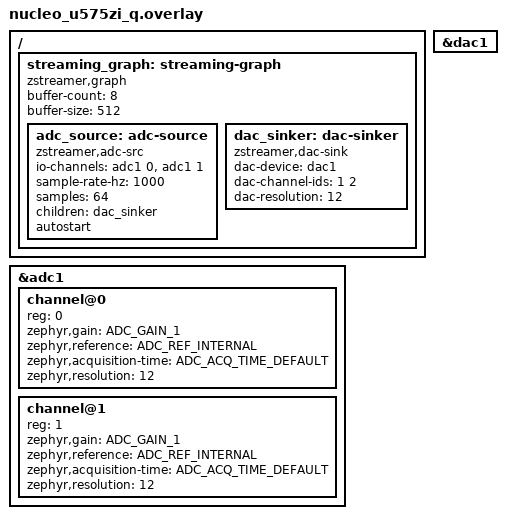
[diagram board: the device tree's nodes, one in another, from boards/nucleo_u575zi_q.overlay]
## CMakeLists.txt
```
# Copyright (c) 2026 sharonthecreator
# SPDX-License-Identifier: Apache-2.0

cmake_minimum_required(VERSION 3.20.0)
find_package(Zephyr REQUIRED HINTS $ENV{ZEPHYR_BASE})
project(adc2dac)

target_sources(app PRIVATE src/main.c)
```

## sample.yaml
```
# Copyright (c) 2026 sharonthecreator
# SPDX-License-Identifier: Apache-2.0

sample:
  name: ADC-to-DAC
  description: |
    Captures dual-channel ADC data and outputs it to a dual-channel
    DAC using a zstreamer graph with adc-src and dac-sink nodes.
    Demonstrates multi-channel ADC capture routed to multi-channel
    DAC output.
tests:
  sample.zstreamer.adc2dac:
    tags: zstreamer adc dac
    platform_allow: nucleo_u575zi_q
```

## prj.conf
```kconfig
# Copyright (c) 2026 sharonthecreator
# SPDX-License-Identifier: Apache-2.0

CONFIG_LOG=y

# zstreamer framework
CONFIG_ZSTREAMER=y

CONFIG_ZSTREAMER_ADC_SRC=y
CONFIG_ADC=y

CONFIG_ZSTREAMER_DAC_SINK=y
CONFIG_DAC=y
```

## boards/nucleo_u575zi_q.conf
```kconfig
# Copyright (c) 2026 sharonthecreator
# SPDX-License-Identifier: Apache-2.0
```

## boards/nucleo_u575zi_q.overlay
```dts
/*
 * Copyright (c) 2026 sharonthecreator
 * SPDX-License-Identifier: Apache-2.0
 *
 * ADC-to-DAC sample on Nucleo U575ZI-Q.
 *
 * Captures dual-channel 12-bit ADC data from PA0 (ADC1_IN0) and
 * PA1 (ADC1_IN1) at ~1 kHz and outputs to DAC1 channels 1 and 2.
 */

&adc1 {
	status = "okay";
	#address-cells = <1>;
	#size-cells = <0>;

	channel@0 {
		reg = <0>;
		zephyr,gain = "ADC_GAIN_1";
		zephyr,reference = "ADC_REF_INTERNAL";
		zephyr,acquisition-time = <ADC_ACQ_TIME_DEFAULT>;
		zephyr,resolution = <12>;
	};

	channel@1 {
		reg = <1>;
		zephyr,gain = "ADC_GAIN_1";
		zephyr,reference = "ADC_REF_INTERNAL";
		zephyr,acquisition-time = <ADC_ACQ_TIME_DEFAULT>;
		zephyr,resolution = <12>;
	};
};

&dac1 {
	status = "okay";
};

/ {
	streaming_graph: streaming-graph {
		compatible = "zstreamer,graph";
		buffer-count = <8>;
		buffer-size = <512>;

		adc_source: adc-source {
			compatible = "zstreamer,adc-src";
			io-channels = <&adc1 0>, <&adc1 1>;
			sample-rate-hz = <1000>;
			samples = <64>;
			children = <&dac_sinker>;
			autostart;
		};

		dac_sinker: dac-sinker {
			compatible = "zstreamer,dac-sink";
			dac-device = <&dac1>;
			dac-channel-ids = <1 2>;
			dac-resolution = <12>;
		};
	};
};
```

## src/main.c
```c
/*
 * Copyright (c) 2026 sharonthecreator
 * SPDX-License-Identifier: Apache-2.0
 */

#include <zephyr/device.h>
#include <zephyr/kernel.h>
#include <zephyr/logging/log.h>

#include <zstreamer/source.h>

LOG_MODULE_REGISTER(adc2dac, LOG_LEVEL_INF);

#define ADC_SRC_NODE DT_NODELABEL(adc_source)

int main(void)
{
	const struct device *adc_src = DEVICE_DT_GET(ADC_SRC_NODE);

	/* Pipeline starts automatically via DTS autostart property. */
	LOG_INF("ADC-to-DAC pipeline running (autostart)");

	/* Let it run for a while, then stop */
	k_sleep(K_SECONDS(10));

	LOG_INF("Stopping pipeline");
	zstreamer_source_stop(adc_src);

	LOG_INF("Done");
	return 0;
}
```
